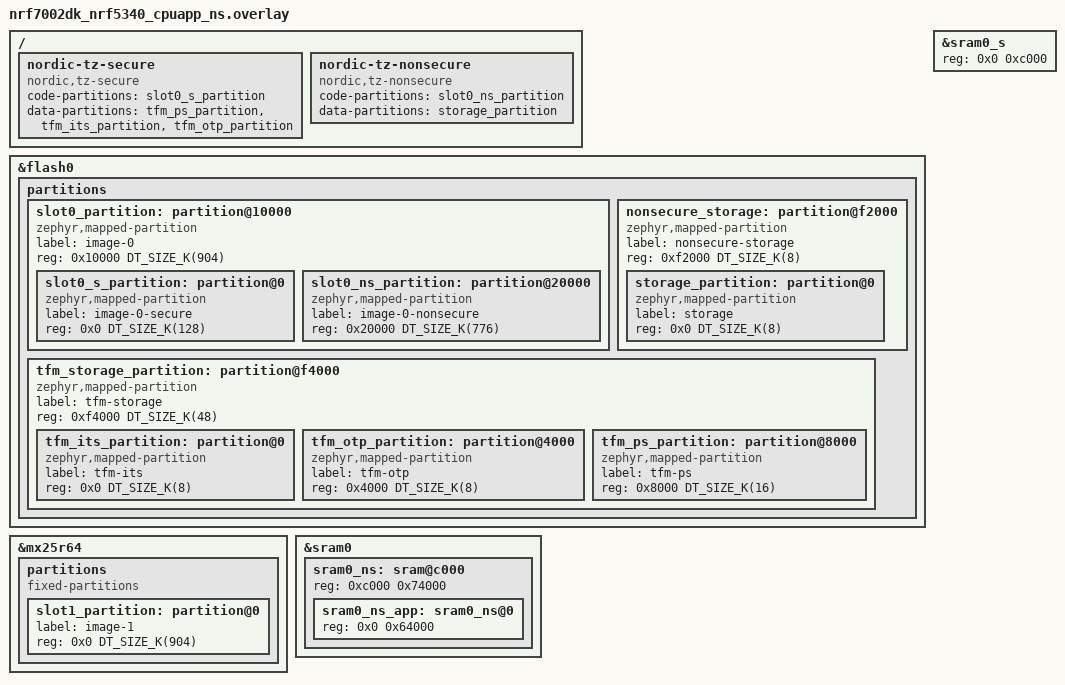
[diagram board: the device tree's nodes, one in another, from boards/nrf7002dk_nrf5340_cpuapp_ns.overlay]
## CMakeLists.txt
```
#
# Copyright (c) 2022 Nordic Semiconductor ASA
#
# SPDX-License-Identifier: LicenseRef-Nordic-5-Clause
#

cmake_minimum_required(VERSION 3.20.0)

find_package(Zephyr REQUIRED HINTS $ENV{ZEPHYR_BASE})
project(nrf_cloud)

# Exactly one of mqtt.conf or coap.conf must be selected
if(NOT CONFIG_NRF_CLOUD_MQTT AND NOT CONFIG_NRF_CLOUD_COAP)
  message(FATAL_ERROR
    "No nRF Cloud transport selected. Build with "
    "-DEXTRA_CONF_FILE=\"mqtt.conf\" or -DEXTRA_CONF_FILE=\"coap.conf\" (or a file list "
    "including one of them).")
elseif(CONFIG_NRF_CLOUD_MQTT AND CONFIG_NRF_CLOUD_COAP)
  message(FATAL_ERROR
    "Both nRF Cloud transports are enabled. Build with only one of "
    "-DEXTRA_CONF_FILE=\"mqtt.conf\" or -DEXTRA_CONF_FILE=\"coap.conf\".")
endif()

# Include certs files if enabled.
zephyr_include_directories_ifdef(CONFIG_NRF_CLOUD_PROVISION_CERTIFICATES certs)

# NORDIC SDK APP START
target_sources(app PRIVATE src/main.c)
target_sources(app PRIVATE src/application.c)
target_sources(app PRIVATE src/cloud_connection.c)
target_sources(app PRIVATE src/message_queue.c)
target_sources(app PRIVATE src/temperature.c)
target_sources(app PRIVATE src/led_control.c)
target_sources(app PRIVATE src/sample_reboot.c)
target_sources(app PRIVATE src/shadow_config.c)

if(CONFIG_LOCATION_TRACKING)
  target_sources(app PRIVATE src/location_tracking.c)
endif()

if(CONFIG_COAP_SHADOW)
  target_sources(app PRIVATE src/shadow_support_coap.c)
endif()

if(CONFIG_SAMPLE_MEMFAULT_FOTA)
  target_sources(app PRIVATE src/memfault_fota_support.c)
endif()

if(CONFIG_SAMPLE_MEMFAULT_BUTTONS)
  target_sources(app PRIVATE src/memfault_buttons.c)
endif()

# NORDIC SDK APP END

zephyr_include_directories(src)
```

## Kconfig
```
#
# Copyright (c) 2022 Nordic Semiconductor ASA
#
# SPDX-License-Identifier: LicenseRef-Nordic-5-Clause
#

menu "Wi-Fi nRF Cloud sample settings"

config APP_VERSION
	string "Wi-Fi nRF Cloud sample version"
	default "1.0.0"

config CLOUD_CONNECTION_RETRY_TIMEOUT_SECONDS
	int "Cloud connection retry timeout (seconds)"
	default 30
	help
	  If connecting to nRF Cloud takes longer than this timeout, it will be
	  reattempted.

config CLOUD_READY_TIMEOUT_SECONDS
	int "Cloud readiness timeout (seconds)"
	default 600
	help
	  If the connection to nRF Cloud does not become ready within this
	  timeout, the sample will reset its connection and try again.

config DATE_TIME_ESTABLISHMENT_TIMEOUT_SECONDS
	int "Date and time establishment timeout (seconds)"
	default 300
	help
	  The sample will wait this many seconds for the device to determine the
	  current date and time before giving up and moving on.

config APPLICATION_THREAD_STACK_SIZE
	int "Application Thread Stack Size (bytes)"
	default 2048
	help
	  Sets the stack size (in bytes) for the application thread of the
	  sample.

config CONNECTION_THREAD_STACK_SIZE
	int "Connection Thread Stack Size (bytes)"
	default 2048
	help
	  Sets the stack size (in bytes) for the connection thread of the
	  sample.

config MESSAGE_THREAD_STACK_SIZE
	int "Message Queue Thread Stack Size (bytes)"
	default 2048
	help
	  Sets the stack size (in bytes) for the message queue processing
	  thread of the sample.

config LED_THREAD_STACK_SIZE
	int "LED Thread Stack Size (bytes)"
	default 1024
	help
	  Sets the stack size (in bytes) for the LED thread.

config MAX_OUTGOING_MESSAGES
	int "Outgoing message maximum"
	default 25
	help
	  Sets the maximum number of device messages which may be enqueued
	  before further messages are dropped.
	  Increasing this value may require an increase to CONFIG_HEAP_MEM_POOL_SIZE.

config MAX_CONSECUTIVE_SEND_FAILURES
	int "Max outgoing consecutive send failures"
	default 5
	help
	  Sets the maximum number of device messages which may fail to send
	  before a connection reset and cooldown is triggered.

config CONSECUTIVE_SEND_FAILURE_COOLDOWN_SECONDS
	int "Cooldown after max consecutive send failures exceeded"
	default 10
	help
	  If a connection reset is triggered by too many failed device
	  messages, the sample will wait this long (in seconds) before trying
	  again.

config SENSOR_SAMPLE_INTERVAL_SECONDS
	int "Sensor sampling interval (seconds)"
	default 60
	help
	  Sets the time to wait between each sensor sample.

menuconfig LOCATION_TRACKING
	bool "Location tracking service"
	default y
	help
	  Uses Wi-Fi information to determine and report device location.

if LOCATION_TRACKING

config LOCATION_TRACKING_SAMPLE_INTERVAL_SECONDS
	int "Location sampling interval (seconds)"
	default 60
	help
	  Sets the location sampling interval in seconds.

endif

config TEMP_TRACKING
	bool "Track temperature"
	default y
	select SENSOR if $(dt_nodelabel_enabled,temp)
	help
	  Sets whether to take temperature measurements.

choice
	prompt "LED indication"
	default LED_INDICATION_GPIO if $(dt_compat_enabled,gpio-leds)
	default LED_INDICATION_DISABLED

config LED_INDICATION_GPIO
	bool "Enable LED indication using the gpio-leds driver"
	select LED
	select LED_GPIO

config LED_INDICATION_DISABLED
	bool "Disable LED indication"

endchoice

choice
	prompt "LED indication LED type"
	depends on !LED_INDICATION_DISABLED
	default LED_INDICATOR_4LED if !LED_INDICATION_DISABLED
	default LED_INDICATOR_NONE

config LED_INDICATOR_4LED
	bool "Four binary LEDs"
	depends on !LED_INDICATION_DISABLED

config LED_INDICATOR_NONE
	bool "No indicator LEDs"
	depends on LED_INDICATION_DISABLED

endchoice

config LED_VERBOSE_INDICATION
	bool "Enables extra LED status indications"
	depends on !LED_INDICATION_DISABLED
	default y

config LED_CONTINUOUS_INDICATION
	bool "Show an idle pattern instead of turning LEDs off"
	depends on !LED_INDICATION_DISABLED
	default y

config TEST_COUNTER
	bool "Sets whether the test counter is enabled"
	help
	  When enabled, the test counter configuration setting in the shadow is ignored.

config TEST_COUNTER_MULTIPLIER
	int "The number of test counter messages sent on each update"
	default 1
	range 1 1000
	help
	  This is a way to increase the number of device messages sent by the sample.
	  It is useful for load testing.

if NRF_CLOUD_COAP

menuconfig COAP_SHADOW
	bool "Updating shadow service"
	default y
	help
	  Updates the shadow with device information. Checks for a shadow
	  delta periodically and processes it if received.

if COAP_SHADOW

config COAP_SHADOW_CHECK_RATE_SECONDS
	int "Shadow job check interval (seconds)"
	default 300
	help
	  Sets the time to wait between each request to get any change to the
	  device shadow.

config COAP_SHADOW_THREAD_STACK_SIZE
	int "CoAP Shadow Thread Stack Size (bytes)"
	default 3072
	help
	  Sets the stack size (in bytes) for the CoAP shadow thread of the
	  sample.

endif

config COAP_SEND_CONFIRMABLE
	bool "Send device messages as confirmable"
	help
	  Ensures all CoAP transfers, even for often less important messages such
	  as sensor data, are sent as confirmable messages.

config SAMPLE_MEMFAULT_FOTA
	bool "Application FOTA using Memfault Release Management"
	depends on BOOTLOADER_MCUBOOT
	depends on $(dt_nodelabel_enabled,slot1_partition)
	depends on MCUBOOT_BOOTLOADER_MODE_SWAP_USING_OFFSET || MCUBOOT_BOOTLOADER_MODE_SWAP_USING_MOVE || \
			MCUBOOT_BOOTLOADER_MODE_SWAP_SCRATCH || MCUBOOT_BOOTLOADER_MODE_RAM_LOAD_WITH_REVERT || \
			MCUBOOT_BOOTLOADER_MODE_DIRECT_XIP_WITH_REVERT
	help
	  Enables application firmware updates delivered through Memfault
	  Release Management. Requires a MCUboot mode that supports the
	  test/confirm revert mechanism, since the sample relies on
	  boot_write_img_confirmed() to mark an update as good.

config SAMPLE_MEMFAULT_BUTTONS
	bool "Trigger Memfault actions with DK buttons"
	default y
	depends on MEMFAULT
	select DK_LIBRARY
	help
	  Lets the application trigger Memfault actions on demand, instead of
	  waiting for the Memfault SDK's periodic upload timer:
	  The first button (sw0) captures a metrics heartbeat and posts all pending chunks.
	  The second button (sw1) checks for a FOTA update (requires SAMPLE_MEMFAULT_FOTA).

config SAMPLE_MEMFAULT_BUTTONS_THREAD_STACK_SIZE
	int "Memfault buttons thread stack size (bytes)"
	default 4096
	depends on SAMPLE_MEMFAULT_BUTTONS
	help
	  Sets the stack size (in bytes) for the thread that runs the
	  button-triggered Memfault actions.

endif

endmenu

if NRF_CLOUD_MQTT
module-str = MQTT nRF Cloud
endif
if NRF_CLOUD_COAP
module-str = CoAP nRF Cloud
endif
module = WIFI_NRF_CLOUD
source "$(ZEPHYR_BASE)/subsys/logging/Kconfig.template.log_config"

menu "Zephyr Kernel"
source "Kconfig.zephyr"
endmenu
```

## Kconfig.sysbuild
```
#
# Copyright (c) 2024 Nordic Semiconductor
#
# SPDX-License-Identifier: LicenseRef-Nordic-5-Clause
#

source "${ZEPHYR_NRF_MODULE_DIR}/samples/wifi/Kconfig.sysbuild.nrf70"

source "share/sysbuild/Kconfig"
```

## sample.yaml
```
sample:
  name: Wi-Fi nRF Cloud Sample
tests:
  sample.wifi.conn.mqtt:
    sysbuild: true
    build_only: true
    integration_platforms:
      - nrf7002dk/nrf5340/cpuapp/ns
      - nrf7120dk/nrf7120/cpuapp/ns
    platform_allow:
      - nrf7002dk/nrf5340/cpuapp/ns
      - nrf7120dk/nrf7120/cpuapp/ns
    extra_args:
      - EXTRA_CONF_FILE="mqtt.conf"
    tags:
      - ci_build
      - sysbuild
      - ci_samples_wifi
  sample.wifi.conn.coap:
    sysbuild: true
    build_only: true
    integration_platforms:
      - nrf7002dk/nrf5340/cpuapp/ns
      - nrf7120dk/nrf7120/cpuapp/ns
    platform_allow:
      - nrf7002dk/nrf5340/cpuapp/ns
      - nrf7120dk/nrf7120/cpuapp/ns
    extra_args:
      - EXTRA_CONF_FILE="coap.conf"
    tags:
      - ci_build
      - sysbuild
      - ci_samples_wifi
  sample.wifi.conn.nrf7002eb2.mqtt:
    sysbuild: true
    build_only: true
    integration_platforms:
      - nrf54lm20dk/nrf54lm20a/cpuapp/ns
      - nrf54lm20dk/nrf54lm20b/cpuapp/ns
    platform_allow:
      - nrf54lm20dk/nrf54lm20a/cpuapp/ns
      - nrf54lm20dk/nrf54lm20b/cpuapp/ns
    extra_args:
      - SHIELD=nrf7002eb2
      - EXTRA_CONF_FILE="mqtt.conf"
    tags:
      - ci_build
      - sysbuild
      - ci_samples_wifi
  sample.wifi.conn.nrf7002eb2.coap:
    sysbuild: true
    build_only: true
    integration_platforms:
      - nrf54lm20dk/nrf54lm20a/cpuapp/ns
      - nrf54lm20dk/nrf54lm20b/cpuapp/ns
    platform_allow:
      - nrf54lm20dk/nrf54lm20a/cpuapp/ns
      - nrf54lm20dk/nrf54lm20b/cpuapp/ns
    extra_args:
      - SHIELD=nrf7002eb2
      - EXTRA_CONF_FILE="coap.conf"
    tags:
      - ci_build
      - sysbuild
      - ci_samples_wifi
```

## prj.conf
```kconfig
#
# Copyright (c) 2022 Nordic Semiconductor ASA
#
# SPDX-License-Identifier: LicenseRef-Nordic-5-Clause
#

# Log level
CONFIG_LOG_PRINTK=y
CONFIG_NET_LOG=y
# For more verbose and detailed log output, set the log level to
# CONFIG_WIFI_NRF_CLOUD_LOG_LEVEL_DBG=y instead.
CONFIG_WIFI_NRF_CLOUD_LOG_LEVEL_INF=y

# General config
CONFIG_EVENTS=y
CONFIG_PICOLIBC_IO_FLOAT=y
CONFIG_RESET_ON_FATAL_ERROR=y
CONFIG_NCS_SAMPLES_DEFAULTS=y

# Improved Logging
# CONFIG_LOG_MODE_DEFERRED allows logging from multiple threads simultaneously without creating
# splintered log entries, at the cost of needing a buffer for storing logs.
CONFIG_LOG_MODE_DEFERRED=y

# CONFIG_LOG_BUFFER_SIZE is the aforementioned buffer. A size of 4096 bytes is useful for debugging
# and prototyping, but is probably more than necessary for production-ready firmware.
CONFIG_LOG_BUFFER_SIZE=4096

# Heap and stacks
# Extended memory heap size needed for Wi-Fi operation and encoding JSON-based nRF Cloud Device Messages.
# Add 256 bytes for each additional Wi-Fi scan result (driver scan max BSS count Kconfig),
# assuming sane SSID lengths.
CONFIG_HEAP_MEM_POOL_SIZE=40144
CONFIG_HEAP_MEM_POOL_IGNORE_MIN=y
CONFIG_SYSTEM_WORKQUEUE_STACK_SIZE=4096
CONFIG_MAIN_STACK_SIZE=2048

# Enable Networking and Connection Manager.
CONFIG_NETWORKING=y
CONFIG_NET_SOCKETS=y
CONFIG_NET_SOCKETS_OFFLOAD=n
CONFIG_NET_MGMT_EVENT_QUEUE_SIZE=30
CONFIG_NET_CONNECTION_MANAGER_MONITOR_STACK_SIZE=6144
CONFIG_NET_CONNECTION_MANAGER=y

CONFIG_NET_IPV4=y
CONFIG_NET_IPV6=y
CONFIG_NET_IPV6_NBR_CACHE=n
CONFIG_NET_IPV6_MLD=n

# DNS
CONFIG_DNS_RESOLVER=y
CONFIG_NET_SOCKETS_DNS_TIMEOUT=30000

# Wi-Fi drivers
CONFIG_WIFI=y


# Wi-Fi conn_mgr bindings
CONFIG_L2_WIFI_CONNECTIVITY=y

# Wi-Fi credentials (simplified Wi-Fi connection setup)
CONFIG_WIFI_CREDENTIALS=y

# Wi-Fi networking and native networking stack
# Note: WIFI_NM_WPA_SUPPLICANT requires 24kB of unused RAM in the final build.
# Memory allocations are fine-tuned with that fact in mind.
CONFIG_WIFI_NM_WPA_SUPPLICANT=y
CONFIG_NET_L2_ETHERNET=y
CONFIG_NET_NATIVE=y
CONFIG_NET_SOCKETS_SOCKOPT_TLS=y
# Allow the FOTA download (HTTPS) to run concurrently with the nRF Cloud CoAP/DTLS conn.
CONFIG_NET_SOCKETS_TLS_MAX_CONTEXTS=2
CONFIG_NET_SOCKETS_TLS_MAX_SESSION_CONTEXTS=2
CONFIG_NET_MAX_CONN=8
CONFIG_NET_MAX_CONTEXTS=8

# Shrink TLS record size and negotiate the smaller size, allowing for
# two concurrent TLS/DTLS sessions (nRF Cloud CoAP + FOTA HTTPS) to fit within the
# available mbedTLS heap (CONFIG_MBEDTLS_HEAP_SIZE).
CONFIG_MBEDTLS_SSL_IN_CONTENT_LEN=4096
CONFIG_MBEDTLS_SSL_OUT_CONTENT_LEN=4096
CONFIG_MBEDTLS_SSL_MAX_FRAGMENT_LENGTH=y

CONFIG_NET_CONTEXT_SNDTIMEO=y
CONFIG_NET_TCP=y
CONFIG_NET_DHCPV4=y

# MBEDTLS base configuration for Wi-Fi TLS/DTLS
CONFIG_MBEDTLS=y
CONFIG_MBEDTLS_ENABLE_HEAP=y
CONFIG_MBEDTLS_SSL_SERVER_NAME_INDICATION=y
CONFIG_MBEDTLS_HEAP_SIZE=65536
# PEM parsing is required for TLS credentials provisioned via the shell
CONFIG_MBEDTLS_PEM_PARSE_C=y
# Needed to parse/verify RSA-signed CA certificates (e.g. Amazon Root CA1, used by
# CONFIG_NRF_CLOUD_PROVISION_CERTIFICATES's hardcoded credentials flow).
CONFIG_MBEDTLS_CIPHERSUITE_TLS_ECDHE_RSA_WITH_AES_128_CBC_SHA256=y
CONFIG_PSA_WANT_ALG_ECDSA=y
# PBKDF2-HMAC is needed for WPA2-PSK passphrase hashing (pbkdf2_sha1)
CONFIG_PSA_WANT_ALG_PBKDF2_HMAC=y
CONFIG_PSA_WANT_ALG_PBKDF2_AES_CMAC_PRF_128=y

# Wait for credential installation to be complete before connecting to nRF Cloud
CONFIG_NRF_CLOUD_CHECK_CREDENTIALS=y

# nRF Cloud
# Transport (MQTT or CoAP) is selected explicitly via mqtt.conf or coap.conf.
CONFIG_NRF_CLOUD=y

# Use compile-time client ID for nRF Cloud
CONFIG_NRF_CLOUD_CLIENT_ID_SRC_HW_ID=y
CONFIG_HW_ID_LIBRARY=y
CONFIG_HW_ID_LIBRARY_SOURCE_DEVICE_ID=y

# Location Services configuration
CONFIG_LOCATION=y
CONFIG_LOCATION_METHOD_WIFI=y
# Keep the Wi-Fi scan result limit Kconfig and
# CONFIG_LOCATION_METHOD_WIFI_SCANNING_RESULTS_MAX_CNT set to the same value.
CONFIG_LOCATION_METHOD_WIFI_SCANNING_RESULTS_MAX_CNT=10

# Date Time lib - Used by main application
CONFIG_DATE_TIME=y
# Enable date_time retries for Wi-Fi
# This prevents occasional DNS lookup flukes from
# rendering the device unable to connect until the next
# CONFIG_DATE_TIME_UPDATE_INTERVAL_SECONDS elapses (default 4 hours)
CONFIG_DATE_TIME_RETRY_COUNT=5
# Use a really short retry interval for demo purposes
# 60 seconds to 15 minutes is probably more appropriate for real-world applications
CONFIG_DATE_TIME_RETRY_INTERVAL_SECONDS=20

# Settings are used by nRF Cloud (MQTT persistent session, FOTA) and for Wi-Fi credentials
# on TFM-less builds. The storage backend (ZMS or NVS) is selected in each board's .conf file.
CONFIG_SETTINGS=y

# Flash
CONFIG_FLASH=y
CONFIG_FLASH_PAGE_LAYOUT=y
CONFIG_FLASH_MAP=y

# Credential management shells
CONFIG_SHELL=y
CONFIG_NET_L2_WIFI_SHELL=y
CONFIG_WIFI_CREDENTIALS_SHELL=y
CONFIG_TLS_CREDENTIALS_SHELL=y
# "net iface" shows MAC + IP; "net ping" useful for connectivity checks
CONFIG_NET_SHELL=y
CONFIG_DEVMEM_SHELL=n
# Persist TLS credentials across reboots.
CONFIG_TLS_CREDENTIALS_BACKEND_PROTECTED_STORAGE=y
# Increased stack size needed for wifi_cred auto_connect command
CONFIG_SHELL_STACK_SIZE=6144
# nRFCloud credentials can exceed 1024 bytes
CONFIG_TLS_CREDENTIALS_SHELL_CRED_BUF_SIZE=3072
# Needed by the TLS credentials shell
CONFIG_BASE64=y

# Network
CONFIG_POSIX_API=y

# Miscellaneous resource allocation tweaks needed to support Wi-Fi
CONFIG_MESSAGE_THREAD_STACK_SIZE=8192
CONFIG_CONNECTION_THREAD_STACK_SIZE=6144
CONFIG_DATE_TIME_THREAD_STACK_SIZE=2048
CONFIG_NET_TX_STACK_SIZE=1024
CONFIG_NET_RX_STACK_SIZE=2048
CONFIG_WIFI_NM_WPA_SUPPLICANT_THREAD_STACK_SIZE=6144
CONFIG_LOCATION_WORKQUEUE_STACK_SIZE=4096
CONFIG_ZVFS_POLL_MAX=8

## Thread stack sizes
CONFIG_APPLICATION_THREAD_STACK_SIZE=2048
CONFIG_NET_MGMT_EVENT_STACK_SIZE=8192

# Enable key generation for nRF Cloud credentials on device, and the associated shell command.
CONFIG_NRF_CLOUD_CREDENTIALS_KEYGEN=y
CONFIG_NRF_CLOUD_CREDENTIALS_KEYGEN_SHELL=y
```

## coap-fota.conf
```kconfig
#
# Copyright (c) 2026 Nordic Semiconductor ASA
#
# SPDX-License-Identifier: LicenseRef-Nordic-5-Clause
#

# We keep FOTA support in a separate file because not all targets
# are able to support it yet (nRF7120/ns). Can be merged into
# coap.conf once things are in shape.

# Set sample-local flag
CONFIG_SAMPLE_MEMFAULT_FOTA=y

# Enable FOTA
CONFIG_FOTA_DOWNLOAD=y
CONFIG_FOTA_DOWNLOAD_PROGRESS_EVT=y
CONFIG_DFU_TARGET=y
CONFIG_DOWNLOADER=y
CONFIG_IMG_MANAGER=y
CONFIG_STREAM_FLASH=y
CONFIG_IMG_ERASE_PROGRESSIVELY=y
CONFIG_REBOOT=y
# CONFIG_NRF_CLOUD_FOTA and CONFIG_NRF_CLOUD_COAP_DOWNLOADS
# are still needed even for Memfault FOTA
CONFIG_NRF_CLOUD_FOTA=y
CONFIG_NRF_CLOUD_COAP_DOWNLOADS=y

# Custom callback to gracefully disconnect from nRF Cloud before reboot
CONFIG_MEMFAULT_FOTA_DOWNLOAD_CALLBACK_CUSTOM=y
# Let Memfault SDK poll for FOTA updates
CONFIG_MEMFAULT_PERIODIC_FOTA_CHECK=y

CONFIG_COAP_CLIENT_MAX_PATH_LENGTH=192
CONFIG_DOWNLOADER_MAX_FILENAME_SIZE=400
CONFIG_DOWNLOADER_STACK_SIZE=8192
```

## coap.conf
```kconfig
#
# Copyright (c) 2024 Nordic Semiconductor ASA
#
# SPDX-License-Identifier: LicenseRef-Nordic-5-Clause
#

# Configure MBEDTLS for CoAP/DTLS
CONFIG_MQTT_LIB_TLS=n
CONFIG_MBEDTLS_DTLS=y
CONFIG_MBEDTLS_SSL_SRV_C=y
CONFIG_MBEDTLS_SSL_COOKIE_C=y
# Ciphersuite for CoAP
CONFIG_MBEDTLS_CIPHERSUITE_TLS_ECDHE_ECDSA_WITH_AES_128_GCM_SHA256=y
CONFIG_MBEDTLS_SSL_DTLS_HELLO_VERIFY=y
CONFIG_MBEDTLS_SSL_DTLS_CONNECTION_ID=y
CONFIG_NET_SOCKETS_ENABLE_DTLS=y

# nRF Cloud: CoAP
CONFIG_NRF_CLOUD_COAP=y
CONFIG_NRF_CLOUD_JWT_SOURCE_CUSTOM=y
CONFIG_NRF_CLOUD_COAP_MAX_USER_OPTIONS=2
CONFIG_COAP_CLIENT_MAX_EXTRA_OPTIONS=3
# Memfault requires longer CoAP options than the default
CONFIG_COAP_EXTENDED_OPTIONS_LEN_VALUE=192

# Memfault
CONFIG_MEMFAULT=y
CONFIG_MEMFAULT_PERIODIC_UPLOAD=y
# Let the application enable upload when ready
CONFIG_MEMFAULT_PERIODIC_UPLOAD_ENABLED_DEFAULT=n
CONFIG_MEMFAULT_USE_NRF_CLOUD_COAP=y
CONFIG_MEMFAULT_SHELL=n
CONFIG_MEMFAULT_NCS_FW_VERSION_STATIC=y
# Dedicated workqueue for Memfault uploads
CONFIG_MEMFAULT_PERIODIC_UPLOAD_USE_DEDICATED_WORKQUEUE=y
# Clean fault logs
CONFIG_MPU_STACK_GUARD=y
CONFIG_MEMFAULT_FAULT_HANDLER_RETURN=y

# CoAP Client
CONFIG_COAP_CLIENT_BLOCK_SIZE=1024
CONFIG_COAP_CLIENT_THREAD_PRIORITY=0
CONFIG_COAP_CLIENT_MAX_PATH_LENGTH=192

# Memfault FOTA
CONFIG_SAMPLE_MEMFAULT_FOTA=y
CONFIG_FOTA_DOWNLOAD=y
CONFIG_FOTA_DOWNLOAD_PROGRESS_EVT=y
CONFIG_DFU_TARGET=y
CONFIG_DOWNLOADER=y
CONFIG_DOWNLOADER_MAX_FILENAME_SIZE=400
CONFIG_IMG_MANAGER=y
CONFIG_STREAM_FLASH=y
CONFIG_IMG_ERASE_PROGRESSIVELY=y
CONFIG_REBOOT=y
# CONFIG_NRF_CLOUD_FOTA and CONFIG_NRF_CLOUD_COAP_DOWNLOADS
# are still needed even for Memfault FOTA
CONFIG_NRF_CLOUD_FOTA=y
CONFIG_NRF_CLOUD_COAP_DOWNLOADS=y
# Custom callback to gracefully disconnect from nRF Cloud before reboot
CONFIG_MEMFAULT_FOTA_DOWNLOAD_CALLBACK_CUSTOM=y
# Let Memfault SDK poll for FOTA updates
CONFIG_MEMFAULT_PERIODIC_FOTA_CHECK=y

# Stack sizes
CONFIG_COAP_CLIENT_STACK_SIZE=8192
CONFIG_COAP_SHADOW_THREAD_STACK_SIZE=8192
CONFIG_DOWNLOADER_STACK_SIZE=8192
```

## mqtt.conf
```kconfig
#
# Copyright (c) 2026 Nordic Semiconductor ASA
#
# SPDX-License-Identifier: LicenseRef-Nordic-5-Clause
#

# Select MQTT as the transport for nRF Cloud
CONFIG_NRF_CLOUD_MQTT=y

## Configure MBEDTLS for MQTT/TLS
CONFIG_MQTT_LIB_TLS=y
CONFIG_MBEDTLS_SSL_SRV_C=n
CONFIG_MBEDTLS_SSL_COOKIE_C=n
```

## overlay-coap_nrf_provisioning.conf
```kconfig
#
# Copyright (c) 2024 Nordic Semiconductor ASA
#
# SPDX-License-Identifier: LicenseRef-Nordic-5-Clause
#

# Enable provisioning library/provisioning shell dependencies
CONFIG_MODEM_JWT=y
CONFIG_MODEM_ATTEST_TOKEN=y

# Enable the provisioning library
CONFIG_NRF_PROVISIONING=y
CONFIG_NRF_PROVISIONING_COAP=y
CONFIG_NRF_PROVISIONING_SCHEDULED=y
CONFIG_NRF_PROVISIONING_AUTO_START_ON_INIT=y

# Enable provisioning shell
CONFIG_SHELL=y
CONFIG_NRF_PROVISIONING_SHELL=y

# Adjust shell buffer sizes to handle nRF Cloud certs
CONFIG_SHELL_BACKEND_SERIAL_RX_RING_BUFFER_SIZE=4096
CONFIG_SHELL_CMD_BUFF_SIZE=4096
CONFIG_SHELL_BACKEND_SERIAL_API_INTERRUPT_DRIVEN=y

# Disable AT host and switch to using shell
CONFIG_AT_HOST_LIBRARY=n
CONFIG_AT_SHELL=y
CONFIG_SHELL_WILDCARD=n

# Configure provisioning message formatting
CONFIG_NRF_PROVISIONING_CODEC=y
CONFIG_NRF_PROVISIONING_CBOR=y
CONFIG_ZCBOR=y

# Include provisioning service certificate as part of the binary.
# Used only if none has been provisioned
CONFIG_NRF_PROVISIONING_WITH_CERT=y
CONFIG_NRF_PROVISIONING_ROOT_CA_SEC_TAG=42

# Max provisioning commands per response
CONFIG_NRF_PROVISIONING_CBOR_RECORDS=10

# Set the provisioning interval to 60 seconds.
# This is a very frequent interval. To save power, set this to something approaching 24 hours.
# But note that provisioning may take up to twice as long as this interval, since it
# happens in two steps.
CONFIG_NRF_PROVISIONING_INTERVAL_S=60

# Request spread factor
CONFIG_NRF_PROVISIONING_SPREAD_S=5

# Adjust provisioning and buffer sizes to handle nRF Cloud certs
CONFIG_NRF_PROVISIONING_RX_BUF_SZ=4096
CONFIG_NRF_PROVISIONING_TX_BUF_SZ=4096
CONFIG_NRF_PROVISIONING_CODEC_AT_CMD_LEN=2048
CONFIG_NRF_PROVISIONING_CODEC_RX_SZ_START=2048

# CoAP Client
CONFIG_COAP_EXTENDED_OPTIONS_LEN_VALUE=192
CONFIG_COAP_CLIENT_THREAD_PRIORITY=0
CONFIG_COAP_CLIENT_BLOCK_SIZE=1024
CONFIG_COAP_CLIENT_MESSAGE_SIZE=1024
CONFIG_COAP_CLIENT_STACK_SIZE=6144
```

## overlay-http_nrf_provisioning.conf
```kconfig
#
# Copyright (c) 2023 Nordic Semiconductor ASA
#
# SPDX-License-Identifier: LicenseRef-Nordic-5-Clause
#

# Enable provisioning library/provisioning shell dependencies
CONFIG_MODEM_JWT=y
CONFIG_MODEM_ATTEST_TOKEN=y

# Enable the provisioning library
CONFIG_NRF_PROVISIONING=y
CONFIG_NRF_PROVISIONING_HTTP=y
CONFIG_NRF_PROVISIONING_SCHEDULED=y
CONFIG_NRF_PROVISIONING_AUTO_START_ON_INIT=y

# Enable provisioning shell
CONFIG_SHELL=y
CONFIG_NRF_PROVISIONING_SHELL=y

# Adjust shell buffer sizes to handle nRF Cloud certs
CONFIG_SHELL_BACKEND_SERIAL_RX_RING_BUFFER_SIZE=4096
CONFIG_SHELL_CMD_BUFF_SIZE=4096

# Disable AT host and switch to using shell
CONFIG_AT_HOST_LIBRARY=n
CONFIG_AT_SHELL=y
CONFIG_SHELL_WILDCARD=n

# Configure provisioning message formatting
CONFIG_NRF_PROVISIONING_CODEC=y
CONFIG_NRF_PROVISIONING_CBOR=y
CONFIG_ZCBOR=y
CONFIG_ZCBOR_CANONICAL=y

# Include provisioning service certificate as part of the binary.
# Used only if none has been provisioned
CONFIG_NRF_PROVISIONING_WITH_CERT=y
CONFIG_NRF_PROVISIONING_ROOT_CA_SEC_TAG=50

# Max provisioning commands per response
CONFIG_NRF_PROVISIONING_CBOR_RECORDS=10

# Set the provisioning interval to 60 seconds.
# This is a very frequent interval. To save power, set this to something approaching 24 hours.
# But note that provisioning may take up to twice as long as this interval, since it
# happens in two steps.
CONFIG_NRF_PROVISIONING_INTERVAL_S=60

# Request spread factor
CONFIG_NRF_PROVISIONING_SPREAD_S=5

# Adjust provisioning and buffer sizes to handle nRF Cloud certs
CONFIG_NRF_PROVISIONING_RX_BUF_SZ=4096
CONFIG_NRF_PROVISIONING_TX_BUF_SZ=4096
CONFIG_NRF_PROVISIONING_CODEC_AT_CMD_LEN=2048
CONFIG_NRF_PROVISIONING_CODEC_RX_SZ_START=2048
```

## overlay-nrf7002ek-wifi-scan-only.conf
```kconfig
#
# Copyright (c) 2022 Nordic Semiconductor ASA
#
# SPDX-License-Identifier: LicenseRef-Nordic-5-Clause
#

# Overlay to use nRF7002 EK on top of nrf9160 DK for Wi-Fi scanning

# Enable the Wi-Fi location method:
CONFIG_LOCATION_TRACKING_WIFI=y
CONFIG_LOCATION_METHOD_WIFI=y
# Align this with CONFIG_NRF_WIFI_SCAN_MAX_BSS_CNT.
# Also see comments for CONFIG_HEAP_MEM_POOL_SIZE.
CONFIG_LOCATION_METHOD_WIFI_SCANNING_RESULTS_MAX_CNT=10

# Enable Wi-Fi drivers
CONFIG_WIFI=y
CONFIG_WIFI_NRF70=y
CONFIG_WIFI_NRF70_SKIP_LOCAL_ADMIN_MAC=y
# Align this with CONFIG_LOCATION_METHOD_WIFI_SCANNING_RESULTS_MAX_CNT.
# Also see comments for CONFIG_HEAP_MEM_POOL_SIZE.
CONFIG_NRF_WIFI_SCAN_MAX_BSS_CNT=10
CONFIG_NET_L2_ETHERNET=y
# We need 2 to ensure nrf9x_socket gets an IP address regardless of order of net_if array
CONFIG_NET_IF_MAX_IPV4_COUNT=2
CONFIG_NET_IF_MAX_IPV6_COUNT=2

# But disable the supplicant, since we don't need connectivity
CONFIG_WIFI_NM_WPA_SUPPLICANT=n
CONFIG_MBEDTLS=n

# Stack/heap tweaks needed to support Wi-Fi.
# Heap allocation should be changed when CONFIG_LOCATION_METHOD_WIFI_SCANNING_RESULTS_MAX_CNT
# and CONFIG_NRF_WIFI_SCAN_MAX_BSS_CNT (which should be the same value) are changed.
CONFIG_NRF_WIFI_CTRL_HEAP_SIZE=10240
CONFIG_HEAP_MEM_POOL_IGNORE_MIN=y
CONFIG_MAIN_STACK_SIZE=2048
CONFIG_NET_MGMT_EVENT_STACK_SIZE=1024

# NET tweaks needed to support Wi-FI
CONFIG_NET_BUF_RX_COUNT=1
CONFIG_NET_BUF_TX_COUNT=1
CONFIG_NET_PKT_RX_COUNT=1
CONFIG_NET_PKT_TX_COUNT=1
CONFIG_NET_TX_STACK_SIZE=512
CONFIG_NET_RX_STACK_SIZE=512
CONFIG_NET_TC_TX_COUNT=1
CONFIG_NET_MAX_CONTEXTS=5

# Disable LED patterns, enabling WiFi scanning takes control of two LEDs
CONFIG_LED_INDICATION_DISABLED=y
```

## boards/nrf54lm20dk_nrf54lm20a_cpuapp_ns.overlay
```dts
/*
 * Copyright (c) 2026 Nordic Semiconductor ASA
 *
 * SPDX-License-Identifier: LicenseRef-Nordic-5-Clause
 */

/* Dual-slot layout for MCUboot (on internal flash) */

/delete-node/ &slot0_s_partition;

/* Shared boot/slot0/slot1 addresses and sizes */
&cpuapp_rram {
	partitions {
		boot_partition: partition@0 {
			compatible = "zephyr,mapped-partition";
			label = "mcuboot";
			reg = <0x0 DT_SIZE_K(64)>;
		};

		slot0_partition: partition@10000 {
			compatible = "zephyr,mapped-partition";
			label = "image-0";
			reg = <0x10000 DT_SIZE_K(964)>;
		};

		slot1_partition: partition@101000 {
			compatible = "zephyr,mapped-partition";
			label = "image-1";
			reg = <0x101000 DT_SIZE_K(964)>;
		};
	};
};

/delete-node/ &tfm_ps_partition;
/delete-node/ &tfm_its_partition;
/delete-node/ &tfm_otp_partition;
/delete-node/ &slot0_ns_partition;
/delete-node/ &storage_partition;
/delete-node/ &sram0_ns;

&slot0_partition {
	ranges = <0x0 0x10000 DT_SIZE_K(964)>;
	#address-cells = <1>;
	#size-cells = <1>;

	slot0_s_partition: partition@0 {
		compatible = "zephyr,mapped-partition";
		label = "image-0-secure";
		reg = <0x0 DT_SIZE_K(120)>;
	};

	slot0_ns_partition: partition@1e000 {
		compatible = "zephyr,mapped-partition";
		label = "image-0-nonsecure";
		reg = <0x1e000 DT_SIZE_K(844)>;
	};
};

&slot1_partition {
	ranges = <0x0 0x101000 DT_SIZE_K(964)>;
	#address-cells = <1>;
	#size-cells = <1>;

	slot1_s_partition: partition@0 {
		compatible = "zephyr,mapped-partition";
		label = "image-1-secure";
		reg = <0x0 DT_SIZE_K(120)>;
	};

	slot1_ns_partition: partition@1e000 {
		compatible = "zephyr,mapped-partition";
		label = "image-1-nonsecure";
		reg = <0x1e000 DT_SIZE_K(844)>;
	};
};

&cpuapp_rram {
	partitions {
		tfm_storage_partition: partition@1f2000 {
			compatible = "zephyr,mapped-partition";
			label = "tfm-storage";
			reg = <0x1f2000 DT_SIZE_K(32)>;
			ranges = <0x0 0x1f2000 DT_SIZE_K(32)>;
			#address-cells = <1>;
			#size-cells = <1>;

			tfm_its_partition: partition@0 {
				compatible = "zephyr,mapped-partition";
				label = "tfm-its";
				reg = <0x0 DT_SIZE_K(8)>;
			};

			tfm_otp_partition: partition@2000 {
				compatible = "zephyr,mapped-partition";
				label = "tfm-otp";
				reg = <0x2000 DT_SIZE_K(8)>;
			};

			tfm_ps_partition: partition@4000 {
				compatible = "zephyr,mapped-partition";
				label = "tfm-ps";
				reg = <0x4000 DT_SIZE_K(16)>;
			};
		};

		storage_partition: partition@1fa000 {
			compatible = "zephyr,mapped-partition";
			label = "storage";
			reg = <0x1fa000 DT_SIZE_K(12)>;
		};
	};
};

/*
 * TrustZone SRAM split. TF-M occupies the low 48 KiB (0xc000) of cpuapp SRAM;
 * the NS application therefore starts at 0x20000000 + 0xc000 = 0x2000c000.
 *
 * nRF54LM20A/B has 512 KiB of SRAM but only 511 KiB (0x7fe40 bytes) is physically
 * accessible. NS SRAM = 0x7fe40 - 0xc000 = 0x73e40 bytes.
 */
&sram0_s {
	reg = <0x0 0xc000>;
	ranges = <0x0 0x0 0xc000>;
};

&cpuapp_sram {
	sram0_ns: image_ns@c000 {
		#address-cells = <1>;
		#size-cells = <1>;
		reg = <0xc000 0x73e40>;
		ranges = <0x0 0xc000 0x73e40>;
	};
};
```

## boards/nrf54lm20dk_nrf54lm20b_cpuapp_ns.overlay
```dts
/*
 * Copyright (c) 2026 Nordic Semiconductor ASA
 *
 * SPDX-License-Identifier: LicenseRef-Nordic-5-Clause
 */

/delete-node/ &slot0_s_partition;
/delete-node/ &tfm_ps_partition;
/delete-node/ &tfm_its_partition;
/delete-node/ &tfm_otp_partition;
/delete-node/ &slot0_ns_partition;
/delete-node/ &storage_partition;
/delete-node/ &sram0_ns;

&cpuapp_rram {
	partitions {
		slot0_s_partition: partition@0 {
			compatible = "zephyr,mapped-partition";
			label = "image-0-secure";
			reg = <0x0 0x24000>;
		};

		tfm_storage_partition: partition@24000 {
			compatible = "zephyr,mapped-partition";
			label = "tfm-storage";
			reg = <0x24000 DT_SIZE_K(32)>;
			ranges = <0x0 0x24000 DT_SIZE_K(32)>;
			#address-cells = <1>;
			#size-cells = <1>;

			tfm_its_partition: partition@0 {
				compatible = "zephyr,mapped-partition";
				label = "tfm-its";
				reg = <0x0 DT_SIZE_K(8)>;
			};

			tfm_otp_partition: partition@2000 {
				compatible = "zephyr,mapped-partition";
				label = "tfm-otp";
				reg = <0x2000 DT_SIZE_K(8)>;
			};

			tfm_ps_partition: partition@4000 {
				compatible = "zephyr,mapped-partition";
				label = "tfm-ps";
				reg = <0x4000 DT_SIZE_K(16)>;
			};
		};

		slot0_ns_partition: partition@2c000 {
			compatible = "zephyr,mapped-partition";
			label = "image-0-nonsecure";
			reg = <0x2c000 0x1cf000>;
		};

		nonsecure_storage: partition@1fb000 {
			compatible = "zephyr,mapped-partition";
			label = "nonsecure-storage";
			reg = <0x1fb000 DT_SIZE_K(8)>;
			ranges = <0x0 0x1fb000 DT_SIZE_K(8)>;
			#address-cells = <1>;
			#size-cells = <1>;

			storage_partition: partition@0 {
				compatible = "zephyr,mapped-partition";
				label = "storage";
				reg = <0x0 DT_SIZE_K(8)>;
			};
		};
	};
};

/*
 * TrustZone SRAM split. TF-M occupies the low 48 KiB (0xc000) of cpuapp SRAM;
 * the NS application therefore starts at 0x20000000 + 0xc000 = 0x2000c000.
 *
 * nRF54LM20B has 512 KiB of SRAM but only 511 KiB (0x7fe40 bytes) is physically
 * accessible. NS SRAM = 0x7fe40 - 0xc000 = 0x73e40 bytes.
 */
&sram0_s {
	reg = <0x0 0xc000>;
	ranges = <0x0 0x0 0xc000>;
};

&cpuapp_sram {
	sram0_ns: image_ns@c000 {
		#address-cells = <1>;
		#size-cells = <1>;
		reg = <0xc000 0x73e40>;
		ranges = <0x0 0xc000 0x73e40>;
	};
};
```

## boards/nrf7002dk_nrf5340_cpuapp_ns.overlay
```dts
/*
 * Copyright (c) 2026 Nordic Semiconductor ASA
 *
 * SPDX-License-Identifier: LicenseRef-Nordic-5-Clause
 */

/* Dual-slot layout for MCUboot (with external flash for slot1) */

/delete-node/ &slot0_partition;
/delete-node/ &slot1_partition;
/delete-node/ &tfm_ps_partition;
/delete-node/ &tfm_its_partition;
/delete-node/ &tfm_otp_partition;
/delete-node/ &storage_partition;
/delete-node/ &sram0_ns;

/* Shared slot0/slot1 addresses and sizes */

&flash0 {
	partitions {
		slot0_partition: partition@10000 {
			compatible = "zephyr,mapped-partition";
			label = "image-0";
			reg = <0x10000 DT_SIZE_K(904)>;
		};
	};
};

&mx25r64 {
	partitions {
		compatible = "fixed-partitions";
		#address-cells = <1>;
		#size-cells = <1>;

		slot1_partition: partition@0 {
			label = "image-1";
			reg = <0x0 DT_SIZE_K(904)>;
		};
	};
};

&slot0_partition {
	ranges = <0x0 0x10000 DT_SIZE_K(904)>;
	#address-cells = <1>;
	#size-cells = <1>;

	slot0_s_partition: partition@0 {
		compatible = "zephyr,mapped-partition";
		label = "image-0-secure";
		reg = <0x0 DT_SIZE_K(128)>;
	};

	slot0_ns_partition: partition@20000 {
		compatible = "zephyr,mapped-partition";
		label = "image-0-nonsecure";
		reg = <0x20000 DT_SIZE_K(776)>;
	};
};

&flash0 {
	partitions {
		/* 0x10000 (boot_partition) + 904K (slot0_partition) = 0xf2000 */
		nonsecure_storage: partition@f2000 {
			compatible = "zephyr,mapped-partition";
			label = "nonsecure-storage";
			reg = <0xf2000 DT_SIZE_K(8)>;
			ranges = <0x0 0xf2000 DT_SIZE_K(8)>;
			#address-cells = <1>;
			#size-cells = <1>;

			storage_partition: partition@0 {
				compatible = "zephyr,mapped-partition";
				label = "storage";
				reg = <0x0 DT_SIZE_K(8)>;
			};
		};

		/* 0xf2000 + 8K = 0xf4000; ends exactly at 0x100000 (1 MiB, end of flash0) */
		tfm_storage_partition: partition@f4000 {
			compatible = "zephyr,mapped-partition";
			label = "tfm-storage";
			reg = <0xf4000 DT_SIZE_K(48)>;
			ranges = <0x0 0xf4000 DT_SIZE_K(48)>;
			#address-cells = <1>;
			#size-cells = <1>;

			tfm_its_partition: partition@0 {
				compatible = "zephyr,mapped-partition";
				label = "tfm-its";
				reg = <0x0 DT_SIZE_K(8)>;
			};

			tfm_otp_partition: partition@4000 {
				compatible = "zephyr,mapped-partition";
				label = "tfm-otp";
				reg = <0x4000 DT_SIZE_K(8)>;
			};

			tfm_ps_partition: partition@8000 {
				compatible = "zephyr,mapped-partition";
				label = "tfm-ps";
				reg = <0x8000 DT_SIZE_K(16)>;
			};
		};
	};
};

/*
 * TrustZone SRAM split from devicetree (region_defs.h for TF-M). The secure image uses
 * 48 KiB (0xc000) at the base of cpuapp SRAM (&sram0_s); NS RAM begins at 0x20000000 + 0xc000.
 * &sram0_ns spans 0x74000 bytes; &sram0_ns_app is 0x64000 because the top 0x10000 (64 KiB)
 * within that NS window is sram0_shared for application/network-core IPC
 * (nrf5340_shared_sram_partition.dtsi), i.e. 0x64000 + 0x10000 == 0x74000.
 */
&sram0_s {
	reg = <0x0 0xc000>;
};

&sram0 {
	sram0_ns: sram@c000 {
		#address-cells = <1>;
		#size-cells = <1>;
		reg = <0xc000 0x74000>;
		ranges = <0x0 0xc000 0x74000>;

		sram0_ns_app: sram0_ns@0 {
			reg = <0x0 0x64000>;
		};
	};
};

/ {
	/delete-node/ nordic-tz-secure;
	/delete-node/ nordic-tz-nonsecure;

	nordic-tz-secure {
		compatible = "nordic,tz-secure";
		code-partitions = <&slot0_s_partition>;
		data-partitions = <&tfm_ps_partition>,
				  <&tfm_its_partition>,
				  <&tfm_otp_partition>;
	};

	nordic-tz-nonsecure {
		compatible = "nordic,tz-nonsecure";
		code-partitions = <&slot0_ns_partition>;
		data-partitions = <&storage_partition>;
	};
};
```

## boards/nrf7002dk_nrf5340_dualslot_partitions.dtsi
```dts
/*
 * Copyright (c) 2026 Nordic Semiconductor ASA
 *
 * SPDX-License-Identifier: LicenseRef-Nordic-5-Clause
 */

/* Shared slot0/slot1 addresses and sizes */

&flash0 {
	partitions {
		slot0_partition: partition@10000 {
			compatible = "zephyr,mapped-partition";
			label = "image-0";
			reg = <0x10000 DT_SIZE_K(904)>;
		};
	};
};

&mx25r64 {
	partitions {
		compatible = "fixed-partitions";
		#address-cells = <1>;
		#size-cells = <1>;

		slot1_partition: partition@0 {
			label = "image-1";
			reg = <0x0 DT_SIZE_K(904)>;
		};
	};
};
```

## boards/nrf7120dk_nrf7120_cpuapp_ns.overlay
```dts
/*
 * Copyright (c) 2026 Nordic Semiconductor ASA
 *
 * SPDX-License-Identifier: LicenseRef-Nordic-5-Clause
 */

&cpuapp_mram {
	/delete-node/ partitions;
};

&cpuapp_mram {
	/*
	 * NVM layout on nRF7120 NS Application MCU with MCUboot. The secure image
	 * is set to 160 KB to fit below the Wi-Fi ROM patch at 0x0010_0000:
	 *
	 * 0x0000_0000 Boot Partition (64 KB)
	 *
	 * 0x0001_0000 Primary image area (1952 KB):
	 *   - 0x0001_0000 Secure image primary (160 KB)
	 *   - 0x0003_8000 Non-secure image primary (1792 KB)
	 *
	 * 0x001F_8000 Secondary image area (1952 KB):
	 *   - 0x001F_8000 Secure image secondary (160 KB)
	 *   - 0x0022_0000 Non-secure image secondary (1792 KB)
	 *
	 * 0x003E_0000 Protected Storage Area (16 KB)
	 * 0x003E_4000 Internal Trusted Storage Area (16 KB)
	 * 0x003E_8000 OTP / NV counters area (8 KB)
	 *
	 * 0x003E_A000 Non-secure storage, used when built with NRF_NS_STORAGE=ON,
	 *             otherwise unused (68 KB)
	 */
	partitions {
		#address-cells = <1>;
		#size-cells = <1>;
		ranges;

		boot_partition: partition@0 {
			compatible = "zephyr,mapped-partition";
			label = "mcuboot";
			reg = <0x00000000 DT_SIZE_K(64)>;
		};

		slot0_partition: partition@10000 {
			compatible = "zephyr,mapped-partition";
			label = "image-0";
			reg = <0x00010000 DT_SIZE_K(1952)>;
			ranges = <0x0 0x00010000 DT_SIZE_K(1952)>;
			#address-cells = <1>;
			#size-cells = <1>;

			slot0_s_partition: partition@0 {
				compatible = "zephyr,mapped-partition";
				label = "image-0-secure";
				reg = <0x0 DT_SIZE_K(160)>;
			};

			slot0_ns_partition: partition@28000 {
				compatible = "zephyr,mapped-partition";
				label = "image-0-nonsecure";
				reg = <0x28000 DT_SIZE_K(1792)>;
			};
		};

		slot1_partition: partition@1f8000 {
			compatible = "zephyr,mapped-partition";
			label = "image-1";
			reg = <0x001f8000 DT_SIZE_K(1952)>;
			ranges = <0x0 0x001f8000 DT_SIZE_K(1952)>;
			#address-cells = <1>;
			#size-cells = <1>;

			slot1_s_partition: partition@0 {
				compatible = "zephyr,mapped-partition";
				label = "image-1-secure";
				reg = <0x0 DT_SIZE_K(160)>;
			};

			slot1_ns_partition: partition@28000 {
				compatible = "zephyr,mapped-partition";
				label = "image-1-nonsecure";
				reg = <0x28000 DT_SIZE_K(1792)>;
			};
		};

		tfm_ps_partition: partition@3e0000 {
			compatible = "zephyr,mapped-partition";
			label = "tfm-ps";
			reg = <0x003e0000 DT_SIZE_K(16)>;
		};

		tfm_its_partition: partition@3e4000 {
			compatible = "zephyr,mapped-partition";
			label = "tfm-its";
			reg = <0x003e4000 DT_SIZE_K(16)>;
		};

		tfm_otp_partition: partition@3e8000 {
			compatible = "zephyr,mapped-partition";
			label = "tfm-otp";
			reg = <0x003e8000 DT_SIZE_K(8)>;
		};

		storage_partition: partition@3ea000 {
			compatible = "zephyr,mapped-partition";
			label = "storage";
			reg = <0x003ea000 DT_SIZE_K(68)>;
		};
	};
};

/ {
	chosen {
		zephyr,code-partition = &slot0_ns_partition;
	};
};
```

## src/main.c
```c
/* Copyright (c) 2023 Nordic Semiconductor ASA
 *
 * SPDX-License-Identifier: LicenseRef-Nordic-5-Clause
 */

#include <zephyr/kernel.h>
#include <stdio.h>
#include <zephyr/logging/log.h>
#include "application.h"
#include "cloud_connection.h"
#include "message_queue.h"
#include "led_control.h"
#if defined(CONFIG_NRF_CLOUD_COAP)
#include "shadow_support_coap.h"
#endif
#if defined(CONFIG_SAMPLE_MEMFAULT_FOTA)
#include "memfault_fota_support.h"
#endif
#if defined(CONFIG_SAMPLE_MEMFAULT_BUTTONS)
#include "memfault_buttons.h"
#endif

LOG_MODULE_REGISTER(main, CONFIG_WIFI_NRF_CLOUD_LOG_LEVEL);

/* Here, we start the various threads that our application will run in */

#ifndef CONFIG_LED_INDICATION_DISABLED
/* Define, and automatically start the LED animation thread. See led_control.c */
K_THREAD_DEFINE(led_thread, CONFIG_LED_THREAD_STACK_SIZE, led_animation_thread_fn,
		NULL, NULL, NULL, 0, 0, 0);
#endif

/* Define, and automatically start the main application thread. See application.c */
K_THREAD_DEFINE(app_thread, CONFIG_APPLICATION_THREAD_STACK_SIZE, main_application_thread_fn,
		NULL, NULL, NULL, 0, 0, 0);

/* Define, and automatically start the message queue thread. See message_queue.c */
K_THREAD_DEFINE(msg_thread, CONFIG_MESSAGE_THREAD_STACK_SIZE, message_queue_thread_fn,
		NULL, NULL, NULL, 0, 0, 0);

/* Define, and automatically start the cloud connection thread. See cloud_connection.c */
K_THREAD_DEFINE(con_thread, CONFIG_CONNECTION_THREAD_STACK_SIZE, cloud_connection_thread_fn,
		NULL, NULL, NULL, 0, 0, 0);

#if defined(CONFIG_NRF_CLOUD_COAP)

#if defined(CONFIG_COAP_SHADOW)
/* Define, and automatically start the CoAP shadow check thread. See shadow_support_coap.c */
K_THREAD_DEFINE(coap_shadow, CONFIG_COAP_SHADOW_THREAD_STACK_SIZE, coap_shadow_thread_fn,
		NULL, NULL, NULL, 0, 0, 0);
#endif
#endif /* CONFIG_NRF_CLOUD_COAP */

#if defined(CONFIG_SAMPLE_MEMFAULT_BUTTONS)
/* Define, and automatically start the Memfault buttons thread. See memfault_buttons.c */
K_THREAD_DEFINE(mflt_buttons, CONFIG_SAMPLE_MEMFAULT_BUTTONS_THREAD_STACK_SIZE,
		memfault_buttons_thread_fn, NULL, NULL, NULL, 0, 0, 0);
#endif

/* main() is called from the main thread, which defaults to priority zero,
 * but for illustrative purposes we don't use it. main_application() could be called directly
 * from this function, rather than given its own dedicated thread.
 */
int main(void)
{
	const char *protocol;

	if (IS_ENABLED(CONFIG_NRF_CLOUD_MQTT)) {
		protocol = "MQTT";
	} else if (IS_ENABLED(CONFIG_NRF_CLOUD_COAP)) {
		protocol = "CoAP";
	}

	LOG_INF("Wi-Fi nRF Cloud sample has started, version: %s, protocol: %s",
		CONFIG_APP_VERSION, protocol);

#if defined(CONFIG_MEMFAULT_NCS_FW_VERSION_STATIC)
	LOG_INF("Memfault software_version: %s", CONFIG_MEMFAULT_NCS_FW_VERSION);
#endif

#if defined(CONFIG_SAMPLE_MEMFAULT_FOTA)
	/* Confirm the running image so MCUboot does not roll back after a successful
	 * FOTA update reboot. FOTA checks/downloads themselves are driven periodically by
	 * the Memfault SDK (see CONFIG_MEMFAULT_PERIODIC_FOTA_CHECK), or on demand by a
	 * button press (see memfault_buttons.c).
	 */
	memfault_fota_support_init();
#endif

	return 0;
}
```

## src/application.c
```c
/* Copyright (c) 2023 Nordic Semiconductor ASA
 *
 * SPDX-License-Identifier: LicenseRef-Nordic-5-Clause
 */

#include <zephyr/kernel.h>
#include <zephyr/logging/log.h>
#include <zephyr/logging/log_ctrl.h>
#include <helpers/nrfx_reset_reason.h>
#include <date_time.h>
#include <stdio.h>
#include <net/nrf_cloud.h>
#include <net/nrf_cloud_codec.h>
#if defined(CONFIG_NRF_CLOUD_COAP)
#include <net/nrf_cloud_coap.h>
#endif
#if defined(CONFIG_LOCATION_TRACKING)
#include <modem/location.h>
#include "location_tracking.h"
#endif
#include "application.h"
#include "temperature.h"
#include "cloud_connection.h"
#include "message_queue.h"
#include "led_control.h"
#include "shadow_config.h"

LOG_MODULE_REGISTER(application, CONFIG_WIFI_NRF_CLOUD_LOG_LEVEL);

/* Timer used to time the sensor sampling rate. */
static K_TIMER_DEFINE(sensor_sample_timer, NULL, NULL);

/* State of the test counter. This can be changed using the configuration in the shadow */
static bool test_counter_enabled;

/**
 * @brief Construct a device message object with automatically generated timestamp
 *
 * The resultant JSON object will be conformal to the General Message Schema described in the
 * application-protocols repo:
 *
 * https://github.com/nRFCloud/application-protocols
 *
 * @param msg - The object to contain the message
 * @param appid - The appId for the device message
 * @param msg_type - The messageType for the device message
 * @return int - 0 on success, negative error code otherwise.
 */
/**
 * @brief Transmit a collected sensor sample to nRF Cloud.
 *
 * @param sensor - The name of the sensor which was sampled.
 * @param value - The sampled sensor value.
 * @return int - 0 on success, negative error code otherwise.
 */
static int send_sensor_sample(const char *const sensor, double value)
{
	int ret;

	MSG_OBJ_DEFINE(msg_obj);

	/* Create a timestamped message container object for the sensor sample. */
	ret = nrf_cloud_obj_msg_ts_init(&msg_obj, sensor,
						NRF_CLOUD_JSON_MSG_TYPE_VAL_DATA);
	if (ret) {
		return -EINVAL;
	}

	/* Populate the container object with the sensor value. */
	ret = nrf_cloud_obj_num_add(&msg_obj, NRF_CLOUD_JSON_DATA_KEY, value, false);
	if (ret) {
		LOG_ERR("Failed to append value to %s sample container object ",
			sensor);
		nrf_cloud_obj_free(&msg_obj);
		return -ENOMEM;
	}

	/* Send the sensor sample container object as a device message. */
	return send_device_message(&msg_obj);
}

#if defined(CONFIG_LOCATION_TRACKING)
/**
 * @brief Callback to receive periodic location updates from location_tracking.c and forward them
 * to nRF Cloud.
 *
 * @param location_data - The received location update.
 *
 */
static void on_location_update(const struct location_event_data * const location_data)
{
	LOG_INF("Location Updated: lat: %.06f, lon: %.06f, accuracy: %.01f m, Method: %s",
		location_data->location.latitude,
		location_data->location.longitude,
		(double)location_data->location.accuracy,
		location_method_str(location_data->method));
}
#endif /* CONFIG_LOCATION_TRACKING */

/** @brief Send an incrementing test counter message to nRF Cloud.
 * If CONFIG_TEST_COUNTER_MULTIPLIER is greater than 1, the counter will be incremented
 * that many times in a row, and a separate test counter message will be sent for each increment.
 */
static void test_counter_send(void)
{
	static int counter;

	for (int i = 0; i < CONFIG_TEST_COUNTER_MULTIPLIER; i++) {
		LOG_INF("Sent test counter = %d", counter);
		(void)send_sensor_sample("COUNT", counter++);
	}
}

static void print_reset_reason(void)
{
	uint32_t reset_reason;

	reset_reason = nrfx_reset_reason_get();
	nrfx_reset_reason_clear(reset_reason);
	LOG_INF("Reset reason: 0x%x", reset_reason);
}

void main_application_thread_fn(void)
{
	print_reset_reason();

	/* Wait for first connection before starting the application. */
	(void)await_cloud_ready(K_FOREVER);

	/* Wait for the date and time to become known.
	 * This is needed both for location services and for sensor sample timestamping.
	 */
	LOG_INF("Waiting for device to determine current date and time");
	if (!await_date_time_known(K_SECONDS(CONFIG_DATE_TIME_ESTABLISHMENT_TIMEOUT_SECONDS))) {
		LOG_WRN("Failed to determine valid date time. Proceeding anyways");
	} else {
		LOG_INF("Current date and time determined");
	}

#if defined(CONFIG_LOCATION_TRACKING)
	/* Begin tracking location at the configured interval. */
	(void)start_location_tracking(on_location_update,
					CONFIG_LOCATION_TRACKING_SAMPLE_INTERVAL_SECONDS);
#endif

	/* Begin sampling sensors. */
	while (true) {
		/* Start the sensor sample interval timer.
		 * We use a timer here instead of merely sleeping the thread, because the
		 * application thread can be preempted by other threads performing long tasks
		 * (such as periodic location acquisition), and we want to account for these
		 * delays when metering the sample send rate.
		 */
		k_timer_start(&sensor_sample_timer,
			K_SECONDS(CONFIG_SENSOR_SAMPLE_INTERVAL_SECONDS), K_FOREVER);

		if (IS_ENABLED(CONFIG_TEMP_TRACKING)) {
			double temp = -1;

			if (get_temperature(&temp) == 0) {
				LOG_INF("Die temperature is %.1f C", temp);
				(void)send_sensor_sample(NRF_CLOUD_JSON_APPID_VAL_TEMP, temp);
			}
		}

		if (test_counter_enable_get()) {
			test_counter_send();
		}

		/* Wait out any remaining time on the sample interval timer. */
		k_timer_status_sync(&sensor_sample_timer);

		/* If cloud stops being ready due to network trouble or device being deleted
		 * from the cloud, turn off sensors and wait, then restart sensors.
		 */
		if (!await_cloud_ready(K_NO_WAIT) && is_device_deleted()) {
#if defined(CONFIG_LOCATION_TRACKING)
			(void)location_request_cancel();
#endif
			LOG_INF("Cloud not ready. Pausing sensors.");
			(void)await_cloud_ready(K_FOREVER);
			LOG_INF("Cloud is ready. Enabling sensors.");
#if defined(CONFIG_LOCATION_TRACKING)
			/* Begin tracking location at the configured interval. */
			(void)start_location_tracking(on_location_update,
						  CONFIG_LOCATION_TRACKING_SAMPLE_INTERVAL_SECONDS);
#endif
		}
	}
}

void test_counter_enable_set(const bool enable)
{
	if (IS_ENABLED(CONFIG_TEST_COUNTER)) {
		LOG_DBG("CONFIG_TEST_COUNTER is enabled, ignoring state change request");
	} else {
		LOG_DBG("Test counter %s", enable ? "enabled" : "disabled");
		test_counter_enabled = enable;
	}
}

bool test_counter_enable_get(void)
{
	/* When CONFIG_TEST_COUNTER is enabled the test counter is always enabled */
	return (test_counter_enabled || IS_ENABLED(CONFIG_TEST_COUNTER));
}
```

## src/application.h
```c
/* Copyright (c) 2023 Nordic Semiconductor ASA
 *
 * SPDX-License-Identifier: LicenseRef-Nordic-5-Clause
 */

#ifndef _APPLICATION_H_
#define _APPLICATION_H_

#if defined(CONFIG_NRF_CLOUD_MQTT)
#define MSG_OBJ_DEFINE(_obj_name) \
	NRF_CLOUD_OBJ_JSON_DEFINE(_obj_name);
#elif defined(CONFIG_NRF_CLOUD_COAP)
#define MSG_OBJ_DEFINE(_obj_name) \
	NRF_CLOUD_OBJ_COAP_CBOR_DEFINE(_obj_name);
#endif

/**
 * @brief Main application -- Wait for valid connection, start location tracking, and then
 * periodically sample sensors and send them to nRF Cloud.
 */
void main_application_thread_fn(void);

void test_counter_enable_set(const bool enable);
bool test_counter_enable_get(void);

#endif /* _APPLICATION_H_ */
```

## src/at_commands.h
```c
/* Copyright (c) 2023 Nordic Semiconductor ASA
 *
 * SPDX-License-Identifier: LicenseRef-Nordic-5-Clause
 */

#ifndef _AT_CMD_REQUESTS_H_
#define _AT_CMD_REQUESTS_H_

/**
 * @brief Forwards an AT command string to the modem, and returns a pointer
 * to a buffer containing the modem's response, or a human readable error.
 *
 * If CONFIG_NRF_MODEM_LIB is not enabled, the function is not compiled and always
 * returns an error string.
 *
 * Please note that the returned response buffer becomes unsafe to use as soon as
 * the next AT command request is made, so be sure to copy or handle the response before performing
 * another request.
 *
 * Do not modify the string in the returned response buffer.
 *
 * @param cmd - The AT command to execute.
 * @return char* a pointer into a NULL-terminated buffer containing the command response.
 */
#if defined(CONFIG_NRF_MODEM_LIB)
char *execute_at_cmd_request(const char *const cmd);
#else /* CONFIG_NRF_MODEM_LIB */
#define execute_at_cmd_request(...) "AT command requests are not supported by this build!"
#endif /* CONFIG_NRF_MODEM_LIB */

#endif /* _AT_CMD_REQUESTS_H_ */
```

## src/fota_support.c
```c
/* Copyright (c) 2022 Nordic Semiconductor ASA
 *
 * SPDX-License-Identifier: LicenseRef-Nordic-5-Clause
 */

#include <zephyr/kernel.h>
#include <zephyr/logging/log.h>
#include <net/nrf_cloud.h>

#include "fota_support.h"
#include "sample_reboot.h"

LOG_MODULE_REGISTER(fota_support, CONFIG_WIFI_NRF_CLOUD_LOG_LEVEL);

void on_fota_downloaded(void)
{
	sample_reboot_normal();
}

/* You may notice there is no logic to actually receive/download/apply FOTA updates.
 * That is because these features are automatically implemented for MQTT by enabling
 * CONFIG_NRF_CLOUD_FOTA (which is implicitly enabled by CONFIG_NRF_CLOUD_MQTT).
 *
 * Note, also that connection.c is responsible for actually enabling FOTA in the nRF
 * Cloud portal, (by correctly updating the device shadow) as well as for notifying
 * fota_support.c of FOTA download completion.
 */
```
